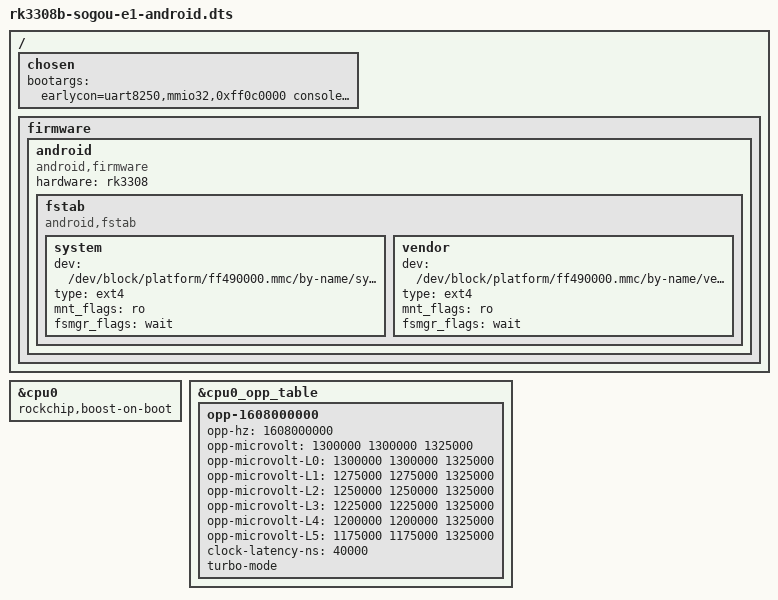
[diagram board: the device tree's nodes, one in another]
// SPDX-License-Identifier: GPL-2.0-only
/dts-v1/;

#include "rk3308b-sogou-e1.dtsi"

/ {
	chosen {
		bootargs = "earlycon=uart8250,mmio32,0xff0c0000 console=ttyFIQ0 androidboot.console=ttyFIQ0 androidboot.hardware=rk3308 androidboot.baseband=N/A init=/init kpti=0 firmware_class.path=/vendor/etc/firmware";
	};

	firmware {
		android {
			compatible = "android,firmware";
			hardware = "rk3308";

			fstab {
				compatible = "android,fstab";

				system {
					dev = "/dev/block/platform/ff490000.mmc/by-name/system";
					type = "ext4";
					mnt_flags = "ro";
					fsmgr_flags = "wait";
				};

				vendor {
					dev = "/dev/block/platform/ff490000.mmc/by-name/vendor";
					type = "ext4";
					mnt_flags = "ro";
					fsmgr_flags = "wait";
				};
			};
		};
	};
};

&cpu0 {
	rockchip,boost-on-boot;
};

&cpu0_opp_table {
	opp-1608000000 {
		opp-hz = /bits/ 64 <1608000000>;
		opp-microvolt = <1300000 1300000 1325000>;
		opp-microvolt-L0 = <1300000 1300000 1325000>;
		opp-microvolt-L1 = <1275000 1275000 1325000>;
		opp-microvolt-L2 = <1250000 1250000 1325000>;
		opp-microvolt-L3 = <1225000 1225000 1325000>;
		opp-microvolt-L4 = <1200000 1200000 1325000>;
		opp-microvolt-L5 = <1175000 1175000 1325000>;
		clock-latency-ns = <40000>;
		turbo-mode;
	};
};
